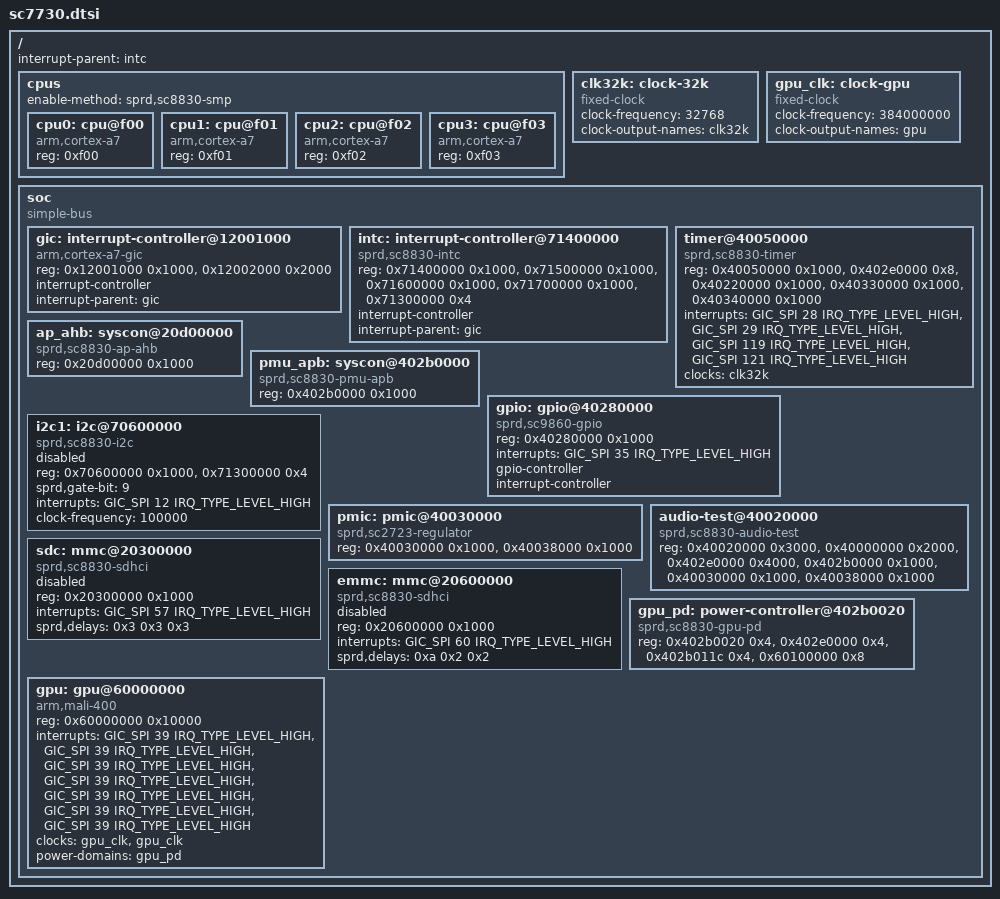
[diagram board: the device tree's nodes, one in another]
// SPDX-License-Identifier: GPL-2.0
/*
 * Spreadtrum SC7730 (SC8830 family) SoC
 *
 * Addresses and interrupts are taken from the vendor 3.10 kernel
 * (sprd-scx35_3.dtsi).
 */

#include <dt-bindings/interrupt-controller/arm-gic.h>
#include <dt-bindings/interrupt-controller/irq.h>

/ {
	#address-cells = <1>;
	#size-cells = <1>;
	interrupt-parent = <&intc>;

	cpus {
		#address-cells = <1>;
		#size-cells = <0>;
		enable-method = "sprd,sc8830-smp";

		cpu0: cpu@f00 {
			device_type = "cpu";
			compatible = "arm,cortex-a7";
			reg = <0xf00>;
		};

		cpu1: cpu@f01 {
			device_type = "cpu";
			compatible = "arm,cortex-a7";
			reg = <0xf01>;
		};

		cpu2: cpu@f02 {
			device_type = "cpu";
			compatible = "arm,cortex-a7";
			reg = <0xf02>;
		};

		cpu3: cpu@f03 {
			device_type = "cpu";
			compatible = "arm,cortex-a7";
			reg = <0xf03>;
		};
	};

	clk32k: clock-32k {
		compatible = "fixed-clock";
		#clock-cells = <0>;
		clock-frequency = <32768>;
		clock-output-names = "clk32k";
	};

	/* set up by gpu_pd: the 384 MHz parent, divider 1 */
	gpu_clk: clock-gpu {
		compatible = "fixed-clock";
		#clock-cells = <0>;
		clock-frequency = <384000000>;
		clock-output-names = "gpu";
	};

	soc {
		compatible = "simple-bus";
		#address-cells = <1>;
		#size-cells = <1>;
		ranges;

		gic: interrupt-controller@12001000 {
			compatible = "arm,cortex-a7-gic";
			reg = <0x12001000 0x1000>,
			      <0x12002000 0x2000>;
			interrupt-controller;
			#interrupt-cells = <3>;
			interrupt-parent = <&gic>;
		};

		/*
		 * Wakeup mirror of the GIC: with all cores in WFI the GIC clock
		 * stops and only sources enabled here can wake the system.
		 */
		intc: interrupt-controller@71400000 {
			compatible = "sprd,sc8830-intc";
			reg = <0x71400000 0x1000>,
			      <0x71500000 0x1000>,
			      <0x71600000 0x1000>,
			      <0x71700000 0x1000>,
			      <0x71300000 0x4>;
			reg-names = "intc0", "intc1", "intc2", "intc3", "eb";
			interrupt-controller;
			#interrupt-cells = <3>;
			interrupt-parent = <&gic>;
		};

		/*
		 * One timer block per CPU: AON GPTIMER0 for CPU0 (also the
		 * clocksource), then AP timers 0-2 for CPUs 1-3. The second
		 * range holds the AON APB clock gates (EB0, EB1).
		 */
		timer@40050000 {
			compatible = "sprd,sc8830-timer";
			reg = <0x40050000 0x1000>,
			      <0x402e0000 0x8>,
			      <0x40220000 0x1000>,
			      <0x40330000 0x1000>,
			      <0x40340000 0x1000>;
			interrupts = <GIC_SPI 28 IRQ_TYPE_LEVEL_HIGH>,
				     <GIC_SPI 29 IRQ_TYPE_LEVEL_HIGH>,
				     <GIC_SPI 119 IRQ_TYPE_LEVEL_HIGH>,
				     <GIC_SPI 121 IRQ_TYPE_LEVEL_HIGH>;
			clocks = <&clk32k>;
		};

		/* holding pen, jump and reset registers of the secondary cores */
		ap_ahb: syscon@20d00000 {
			compatible = "sprd,sc8830-ap-ahb";
			reg = <0x20d00000 0x1000>;
		};

		/* power domains of cores 1-3 (gpu_pd also maps parts of it) */
		pmu_apb: syscon@402b0000 {
			compatible = "sprd,sc8830-pmu-apb";
			reg = <0x402b0000 0x1000>;
		};

		/* 256 digital GPIOs, same layout as the SC9860 */
		gpio: gpio@40280000 {
			compatible = "sprd,sc9860-gpio";
			reg = <0x40280000 0x1000>;
			interrupts = <GIC_SPI 35 IRQ_TYPE_LEVEL_HIGH>;
			gpio-controller;
			#gpio-cells = <2>;
			interrupt-controller;
			#interrupt-cells = <2>;
		};

		/* the older Spreadtrum I2C block; "eb" is the AP APB clock gate */
		i2c1: i2c@70600000 {
			compatible = "sprd,sc8830-i2c";
			reg = <0x70600000 0x1000>, <0x71300000 0x4>;
			reg-names = "i2c", "eb";
			sprd,gate-bit = <9>;
			interrupts = <GIC_SPI 12 IRQ_TYPE_LEVEL_HIGH>;
			clock-frequency = <100000>;
			#address-cells = <1>;
			#size-cells = <0>;
			status = "disabled";
		};

		/* SC2723 PMIC: ADI controller and the PMIC register window */
		pmic: pmic@40030000 {
			compatible = "sprd,sc2723-regulator";
			reg = <0x40030000 0x1000>, <0x40038000 0x1000>;
			reg-names = "adi", "pmic";
		};

		/* Audio bring-up: test tone through VBC + SC2723S codec + speaker PA */
		audio-test@40020000 {
			compatible = "sprd,sc8830-audio-test";
			reg = <0x40020000 0x3000>, <0x40000000 0x2000>,
			      <0x402e0000 0x4000>, <0x402b0000 0x1000>,
			      <0x40030000 0x1000>, <0x40038000 0x1000>;
			reg-names = "vbc", "codec", "aon", "pmu", "adi", "pmic";
		};

		/* SD card slot (vendor "sdio0") */
		sdc: mmc@20300000 {
			compatible = "sprd,sc8830-sdhci";
			reg = <0x20300000 0x1000>;
			interrupts = <GIC_SPI 57 IRQ_TYPE_LEVEL_HIGH>;
			sprd,delays = <0x3 0x3 0x3>;
			status = "disabled";
		};

		/* eMMC (vendor "sdio3"), set up by the bootloader */
		emmc: mmc@20600000 {
			compatible = "sprd,sc8830-sdhci";
			reg = <0x20600000 0x1000>;
			interrupts = <GIC_SPI 60 IRQ_TYPE_LEVEL_HIGH>;
			sprd,delays = <0xa 0x2 0x2>;
			status = "disabled";
		};

		/*
		 * PMU PD_GPU_TOP_CFG, AON APB_EB0 (shared), the PMU gates of the
		 * GPU clock sources and the GPU APB block
		 */
		gpu_pd: power-controller@402b0020 {
			compatible = "sprd,sc8830-gpu-pd";
			reg = <0x402b0020 0x4>,
			      <0x402e0000 0x4>,
			      <0x402b011c 0x4>,
			      <0x60100000 0x8>;
			reg-names = "pmu", "aon", "gate", "gpu";
			#power-domain-cells = <0>;
		};

		gpu: gpu@60000000 {
			compatible = "arm,mali-400";
			reg = <0x60000000 0x10000>;
			/* every unit of the MP2 GPU shares one interrupt line */
			interrupts = <GIC_SPI 39 IRQ_TYPE_LEVEL_HIGH>,
				     <GIC_SPI 39 IRQ_TYPE_LEVEL_HIGH>,
				     <GIC_SPI 39 IRQ_TYPE_LEVEL_HIGH>,
				     <GIC_SPI 39 IRQ_TYPE_LEVEL_HIGH>,
				     <GIC_SPI 39 IRQ_TYPE_LEVEL_HIGH>,
				     <GIC_SPI 39 IRQ_TYPE_LEVEL_HIGH>,
				     <GIC_SPI 39 IRQ_TYPE_LEVEL_HIGH>;
			interrupt-names = "gp", "gpmmu", "pp0", "ppmmu0",
					  "pp1", "ppmmu1", "pmu";
			clocks = <&gpu_clk>, <&gpu_clk>;
			clock-names = "bus", "core";
			power-domains = <&gpu_pd>;
		};
	};
};
